# STM32U073 register map
File version: 1.0
CPU: CM0+ r0p1, little endian, MPU, no FPU, 4 interrupt priority bits
Registers are 32-bit, read-write, reset 0x0 unless marked. A register's access mark holds for its fields unless they carry their own. Offsets are from the block's base; [hi:lo] are bit positions.

## SPI1 — SPI address block description
Base 0x40013000
Same registers: SPI2 0x40003800, SPI3 0x40003C00
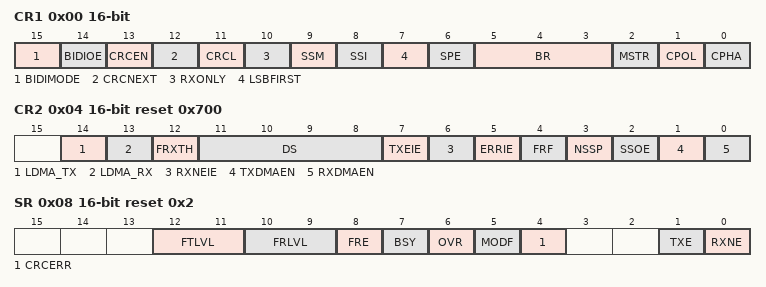
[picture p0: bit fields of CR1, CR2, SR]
0x00 CR1 16-bit — SPI control register 1
  [15] BIDIMODE — Bidirectional data mode enable. This bit enables half-duplex communication using common single bidirectional data line. Keep RXONLY bit clear when bidirectional mode is active.
    0=Unidirectional (2-line unidirectional data mode selected); 1=Bidirectional (1-line bidirectional data mode selected)
  [14] BIDIOE — Output enable in bidirectional mode This bit combined with the BIDIMODE bit selects the direction of transfer in bidirectional mode. Note: In master mode, the MOSI pin is used and in slave mode, the MISO pin is used.
    0=Output disabled (receive-only mode); 1=Output enabled (transmit-only mode)
  [13] CRCEN — Hardware CRC calculation enable Note: This bit should be written only when SPI is disabled (SPE = 0) for correct operation.
    0=Disabled (CRC calculation disabled); 1=Enabled (CRC calculation enabled)
  [12] CRCNEXT — Transmit CRC next Note: This bit has to be written as soon as the last data is written in the SPI_DR register.
    0=TxBuffer (Next transmit value is from Tx buffer); 1=CRC (Next transmit value is from Tx CRC register)
  [11] CRCL — CRC length This bit is set and cleared by software to select the CRC length. Note: This bit should be written only when SPI is disabled (SPE = 0) for correct operation.
    0=EightBit (8-bit CRC length); 1=SixteenBit (16-bit CRC length)
  [10] RXONLY — Receive only mode enabled. This bit enables simplex communication using a single unidirectional line to receive data exclusively. Keep BIDIMODE bit clear when receive only mode is active.This bit is also useful in a multislave system in which this particular slave is not accessed, the output from the accessed slave is not corrupted.
    0=Full duplex (Transmit and receive); 1=Output disabled (Receive-only mode)
  [9] SSM — Software slave management When the SSM bit is set, the NSS pin input is replaced with the value from the SSI bit. Note: This bit is not used in SPI TI mode.
    0=Disabled (Software slave management disabled); 1=Enabled (Software slave management enabled)
  [8] SSI — Internal slave select This bit has an effect only when the SSM bit is set. The value of this bit is forced onto the NSS pin and the I/O value of the NSS pin is ignored. Note: This bit is not used in SPI TI mode.
    0=SlaveSelected (0 is forced onto the NSS pin and the I/O value of the NSS pin is ignored); 1=SlaveNotSelected (1 is forced onto the NSS pin and the I/O value of the NSS pin is ignored)
  [7] LSBFIRST — Frame format Note: 1. This bit should not be changed when communication is ongoing. Note: 2. This bit is not used in SPI TI mode.
    0=MSBFirst (Data is transmitted/received with the MSB first); 1=LSBFirst (Data is transmitted/received with the LSB first)
  [6] SPE — SPI enable Note: When disabling the SPI, follow the procedure described in Procedure for disabling the SPI on page1954.
    0=Disabled (Peripheral disabled); 1=Enabled (Peripheral enabled)
  [5:3] BR — Baud rate control Note: These bits should not be changed when communication is ongoing.
    0=Div2 (f_PCLK / 2); 1=Div4 (f_PCLK / 4); 2=Div8 (f_PCLK / 8); 3=Div16 (f_PCLK / 16); 4=Div32 (f_PCLK / 32); 5=Div64 (f_PCLK / 64); 6=Div128 (f_PCLK / 128); 7=Div256 (f_PCLK / 256)
  [2] MSTR — Master selection Note: This bit should not be changed when communication is ongoing.
    0=Slave configuration; 1=Master configuration
  [1] CPOL — Clock polarity Note: This bit should not be changed when communication is ongoing. Note: This bit is not used in SPI TI mode except the case when CRC is applied at TI mode.
    0=IdleLow (CK to 0 when idle); 1=IdleHigh (CK to 1 when idle)
  [0] CPHA — Clock phase Note: This bit should not be changed when communication is ongoing. Note: This bit is not used in SPI TI mode except the case when CRC is applied at TI mode.
    0=FirstEdge (The first clock transition is the first data capture edge); 1=SecondEdge (The second clock transition is the first data capture edge)
0x04 CR2 16-bit reset 0x700 — SPI control register 2
  [14] LDMA_TX — Last DMA transfer for transmission This bit is used in data packing mode, to define if the total number of data to transmit by DMA is odd or even. It has significance only if the TXDMAEN bit in the SPI_CR2 register is set and if packing mode is used (data length =< 8-bit and write access to SPI_DR is 16-bit wide). It has to be written when the SPI is disabled (SPE = 0 in the SPI_CR1 register). Note: Refer to Procedure for disabling the SPI on page1954 if the CRCEN bit is set.
    0=Even (Number of data to transfer for transmit is even); 1=Odd (Number of data to transfer for transmit is odd)
  [13] LDMA_RX — Last DMA transfer for reception This bit is used in data packing mode, to define if the total number of data to receive by DMA is odd or even. It has significance only if the RXDMAEN bit in the SPI_CR2 register is set and if packing mode is used (data length =< 8-bit and write access to SPI_DR is 16-bit wide). It has to be written when the SPI is disabled (SPE = 0 in the SPI_CR1 register). Note: Refer to Procedure for disabling the SPI on page1954 if the CRCEN bit is set.
    0=Even (Number of data to transfer for receive is even); 1=Odd (Number of data to transfer for receive is odd)
  [12] FRXTH — FIFO reception threshold This bit is used to set the threshold of the RXFIFO that triggers an RXNE event
    0=Half (RXNE event is generated if the FIFO level is greater than or equal to 1/2 (16-bit)); 1=Quarter (RXNE event is generated if the FIFO level is greater than or equal to 1/4 (8-bit))
  [11:8] DS — Data size These bits configure the data length for SPI transfers. If software attempts to write one of the Not used values, they are forced to the value 0111 (8-bit)
    3=FourBit (4-bit); 4=FiveBit (5-bit); 5=SixBit (6-bit); 6=SevenBit (7-bit); 7=EightBit (8-bit); 8=NineBit (9-bit); 9=TenBit (10-bit); 10=ElevenBit (11-bit); 11=TwelveBit (12-bit); 12=ThirteenBit (13-bit); 13=FourteenBit (14-bit); 14=FifteenBit (15-bit); 15=SixteenBit (16-bit)
  [7] TXEIE — Tx buffer empty interrupt enable
    0=Masked (TXE interrupt masked); 1=NotMasked (TXE interrupt not masked)
  [6] RXNEIE — RX buffer not empty interrupt enable
    0=Masked (RXE interrupt masked); 1=NotMasked (RXE interrupt not masked)
  [5] ERRIE — Error interrupt enable This bit controls the generation of an interrupt when an error condition occurs (CRCERR, OVR, MODF in SPI mode, FRE at TI mode).
    0=Masked (Error interrupt masked); 1=NotMasked (Error interrupt not masked)
  [4] FRF — Frame format 1 SPI TI mode Note: This bit must be written only when the SPI is disabled (SPE=0).
    0=Motorola (SPI Motorola mode); 1=TI (SPI TI mode)
  [3] NSSP — NSS pulse management This bit is used in master mode only. it allows the SPI to generate an NSS pulse between two consecutive data when doing continuous transfers. In the case of a single data transfer, it forces the NSS pin high level after the transfer. It has no meaning if CPHA = 1, or FRF = 1. Note: 1. This bit must be written only when the SPI is disabled (SPE=0). Note: 2. This bit is not used in SPI TI mode.
    0=NoPulse (No NSS pulse); 1=PulseGenerated (NSS pulse generated)
  [2] SSOE — SS output enable Note: This bit is not used in SPI TI mode.
    0=Disabled (SS output is disabled in master mode); 1=Enabled (SS output is enabled in master mode)
  [1] TXDMAEN — Tx buffer DMA enable When this bit is set, a DMA request is generated whenever the TXE flag is set.
    0=Disabled (Tx buffer DMA disabled); 1=Enabled (Tx buffer DMA enabled)
  [0] RXDMAEN — Rx buffer DMA enable When this bit is set, a DMA request is generated whenever the RXNE flag is set.
    0=Disabled (Rx buffer DMA disabled); 1=Enabled (Rx buffer DMA enabled)
0x08 SR 16-bit access per field reset 0x2 — SPI status register
  [12:11] FTLVL ro — FIFO transmission level These bits are set and cleared by hardware.
    0=Empty (Tx FIFO Empty); 1=Quarter (Tx 1/4 FIFO); 2=Half (Tx 1/2 FIFO); 3=Full (Tx FIFO full)
  [10:9] FRLVL ro — FIFO reception level These bits are set and cleared by hardware. Note: These bits are not used in SPI receive-only mode while CRC calculation is enabled.
    0=Empty (Rx FIFO Empty); 1=Quarter (Rx 1/4 FIFO); 2=Half (Rx 1/2 FIFO); 3=Full (Rx FIFO full)
  [8] FRE ro — Frame format error This flag is used for SPI in TI slave mode. Refer to Section133.4.11: SPI error flags. This flag is set by hardware and reset when SPI_SR is read by software.
    0=NoError (No frame format error); 1=Error (A frame format error occurred)
  [7] BSY ro — Busy flag This flag is set and cleared by hardware. Note: The BSY flag must be used with caution: refer to Section133.4.10: SPI status flags and Procedure for disabling the SPI on page1954.
    0=NotBusy (SPI not busy); 1=Busy (SPI busy)
  [6] OVR ro — Overrun flag This flag is set by hardware and reset by a software sequence.
    0=No overrun occurred; 1=Overrun occurred
  [5] MODF ro — Mode fault This flag is set by hardware and reset by a software sequence. Refer to Section1: Mode fault (MODF) on page1964 for the software sequence.
    0=NoFault (No mode fault occurred); 1=Fault (Mode fault occurred)
  [4] CRCERR rw write-0-clears — CRC error flag Note: This flag is set by hardware and cleared by software writing 0.
    on read: 0=Match (CRC value received matches the SPIx_RXCRCR value); 1=NoMatch (CRC value received does not match the SPIx_RXCRCR value) | on write: 0=Clear flag
  [1] TXE ro — Transmit buffer empty
    0=NotEmpty (Tx buffer not empty); 1=Empty (Tx buffer empty)
  [0] RXNE ro — Receive buffer not empty
    0=Empty (Rx buffer empty); 1=NotEmpty (Rx buffer not empty)
0x0C DR 16-bit — SPI data register
  [15:0] DR — Data register Data received or to be transmitted The data register serves as an interface between the Rx and Tx FIFOs. When the data register is read, RxFIFO is accessed while the write to data register accesses TxFIFO (See Section133.4.9: Data transmission and reception procedures). Note: Data is always right-aligned. Unused bits are ignored when writing to the register, and read as zero when the register is read. The Rx threshold setting must always correspond with the read access currently used.
0x0C DR8 8-bit (alternate view of DR) — Direct 8-bit access to data register
  [7:0] DR — Data register
0x10 CRCPR 16-bit reset 0x7 — SPI CRC polynomial register
  [15:0] CRCPOLY — CRC polynomial register This register contains the polynomial for the CRC calculation. The CRC polynomial (0x0007) is the reset value of this register. Another polynomial can be configured as required.
0x14 RXCRCR 16-bit ro — SPI Rx CRC register
  [15:0] RXCRC — Rx CRC register When CRC calculation is enabled, the RXCRC[15:0] bits contain the computed CRC value of the subsequently received bytes. This register is reset when the CRCEN bit in SPI_CR1 register is written to 1. The CRC is calculated serially using the polynomial programmed in the SPI_CRCPR register. Only the 8 LSB bits are considered when the CRC frame format is set to be 8-bit length (CRCL bit in the SPI_CR1 is cleared). CRC calculation is done based on any CRC8 standard. The entire 16-bits of this register are considered when a 16-bit CRC frame format is selected (CRCL bit in the SPI_CR1 register is set). CRC calculation is done based on any CRC16 standard. Note: A read to this register when the BSY Flag is set could return an incorrect value.
0x18 TXCRCR 16-bit ro — SPI Tx CRC register
  [15:0] TXCRC — Tx CRC register When CRC calculation is enabled, the TXCRC[7:0] bits contain the computed CRC value of the subsequently transmitted bytes. This register is reset when the CRCEN bit of SPI_CR1 is written to 1. The CRC is calculated serially using the polynomial programmed in the SPI_CRCPR register. Only the 8 LSB bits are considered when the CRC frame format is set to be 8-bit length (CRCL bit in the SPI_CR1 is cleared). CRC calculation is done based on any CRC8 standard. The entire 16-bits of this register are considered when a 16-bit CRC frame format is selected (CRCL bit in the SPI_CR1 register is set). CRC calculation is done based on any CRC16 standard. Note: A read to this register when the BSY flag is set could return an incorrect value.
